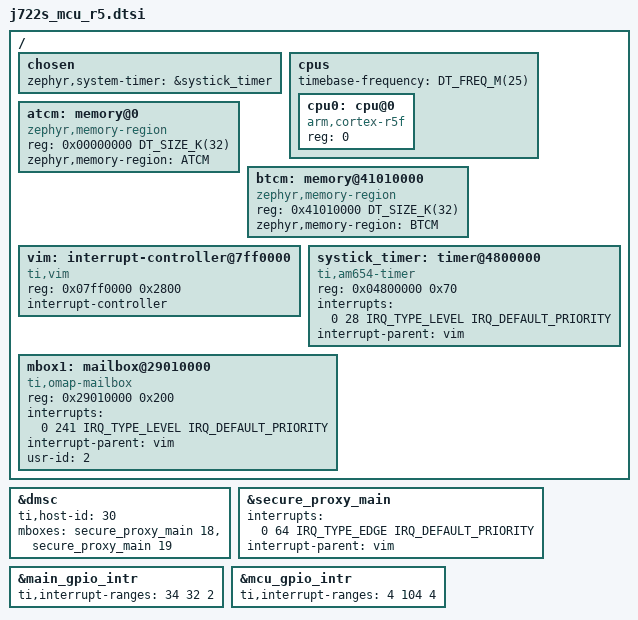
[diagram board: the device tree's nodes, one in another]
/*
 * Copyright (c) 2024 Texas Instruments Incorporated
 *	Andrew Davis <afd@ti.com>
 *
 * SPDX-License-Identifier: Apache-2.0
 */

#include <mem.h>
#include <freq.h>
#include <arm/armv7-r.dtsi>
#include <zephyr/dt-bindings/interrupt-controller/ti-vim.h>

#include "j722s_mcu.dtsi"
#include "j722s_main.dtsi"

/ {
	#address-cells = <1>;
	#size-cells = <1>;

	chosen {
		zephyr,system-timer = &systick_timer;
	};

	cpus {
		#address-cells = <1>;
		#size-cells = <0>;
		timebase-frequency = <DT_FREQ_M(25)>;

		cpu0: cpu@0 {
			device_type = "cpu";
			compatible = "arm,cortex-r5f";
			reg = <0>;
		};
	};

	atcm: memory@0 {
		device_type = "memory";
		compatible = "zephyr,memory-region", "mmio-sram";
		reg = <0x00000000 DT_SIZE_K(32)>;
		zephyr,memory-region = "ATCM";
	};

	btcm: memory@41010000 {
		device_type = "memory";
		compatible = "zephyr,memory-region", "mmio-sram";
		reg = <0x41010000 DT_SIZE_K(32)>;
		zephyr,memory-region = "BTCM";
	};

	vim: interrupt-controller@7ff0000 {
		#address-cells = <1>;
		compatible = "ti,vim";
		reg = <0x07ff0000 0x2800>;
		interrupt-controller;
		#interrupt-cells = <4>; /* {IRQ/FIQ, IRQ_NUM, IRQ_TYPE, IRQ_PRIO} */
		status = "okay";
	};

	systick_timer: timer@4800000 {
		compatible = "ti,am654-timer";
		reg = <0x04800000 0x70>;
		interrupts = <0 28 IRQ_TYPE_LEVEL IRQ_DEFAULT_PRIORITY>;
		interrupt-parent = <&vim>;
		status = "okay";
	};

	mbox1: mailbox@29010000 {
		compatible = "ti,omap-mailbox";
		reg = <0x29010000 0x200>;
		interrupts = <0 241 IRQ_TYPE_LEVEL IRQ_DEFAULT_PRIORITY>;
		interrupt-parent = <&vim>;
		usr-id = <2>;
		#mbox-cells = <1>;
		status = "okay";
	};
};

/* MCU_0_R5_0 (non-secure): host 30, secure-proxy threads 18/19 */
&dmsc {
	ti,host-id = <30>;
	mboxes = <&secure_proxy_main 18>, <&secure_proxy_main 19>;
};

/*
 * MCU secure-proxy response has no direct VIM wire in the TISCI table; use the
 * conventional INTAGGR-backed VIM line 64 (same convention as AM64x R5).
 */
&secure_proxy_main {
	interrupt-names = "rx_18";
	interrupts = <0 64 IRQ_TYPE_EDGE IRQ_DEFAULT_PRIORITY>;
	interrupt-parent = <&vim>;
};

/*
 * MAIN GPIOMUX INTROUTER outputs wired to MCU R5F VIM:
 *   out 34..35 -> VIM 32..33
 */
&main_gpio_intr {
	ti,interrupt-ranges = <34 32 2>;
};

/*
 * WKUP_MCU GPIOMUX INTROUTER outputs wired to MCU R5F VIM:
 *   out 4..7 -> VIM 104..107
 */
&mcu_gpio_intr {
	ti,interrupt-ranges = <4 104 4>;
};
